# H616 register map
Vendor: Allwinner; Series: H616; File version: 0.1
CPU: other 0, little endian, MPU, no FPU, 0 interrupt priority bits
Registers are 32-bit, read-write, reset 0x0 unless marked. A register's access mark holds for its fields unless they carry their own. Offsets are from the block's base; [hi:lo] are bit positions; lines under a group give offsets from that group; {n}, {i} and the like mark numbered series; 'fields as' and 'values as' point back to an identical list; <NAME> marks a mode.

## AHUB
Base 0x05097000
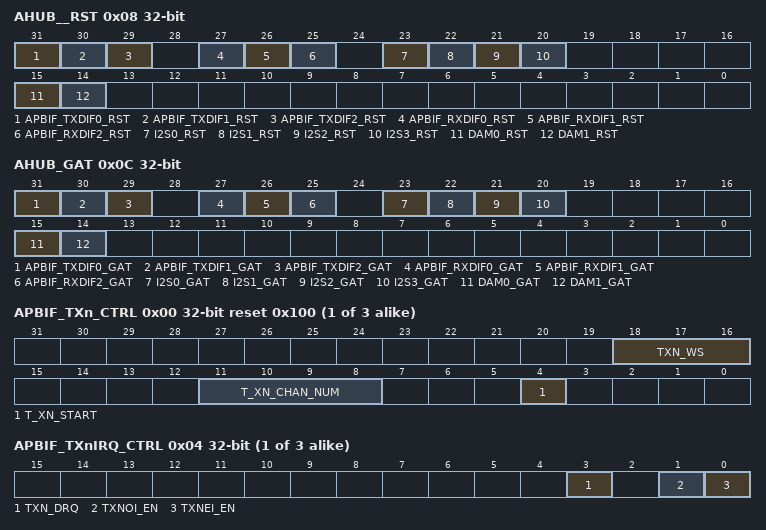
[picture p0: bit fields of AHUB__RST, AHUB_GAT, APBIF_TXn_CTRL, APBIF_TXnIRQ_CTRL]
0x08 AHUB__RST
  [all] fields
    0=Assert; 1=deassert
  [31] APBIF_TXDIF0_RST — 0: Assert 1: De-assert
  [30] APBIF_TXDIF1_RST — 0: Assert 1: De-assert
  [29] APBIF_TXDIF2_RST — 0: Assert 1: De-assert
  [27] APBIF_RXDIF0_RST — 0: Assert 1: De-assert
  [26] APBIF_RXDIF1_RST — 0: Assert 1: De-assert
  [25] APBIF_RXDIF2_RST — 0: Assert 1: De-assert
  [23-n] I2S{n}_RST (n=0..3) — 0: Assert 1: De-assert
  [15] DAM0_RST — 0: Assert 1: De-assert
  [14] DAM1_RST — 0: Assert 1: De-assert
0x0C AHUB_GAT — AHUB Gating
  [all] fields
    0=OFF (Clock is OFF); 1=ON (Clock is ON)
  [31] APBIF_TXDIF0_GAT — 0: Clock is OFF 1: Clock is ON
  [30] APBIF_TXDIF1_GAT — 0: Clock is OFF 1: Clock is ON
  [29] APBIF_TXDIF2_GAT — 0: Clock is OFF 1: Clock is ON
  [27] APBIF_RXDIF0_GAT — 0: Clock is OFF 1: Clock is ON
  [26] APBIF_RXDIF1_GAT — 0: Clock is OFF 1: Clock is ON
  [25] APBIF_RXDIF2_GAT — 0: Clock is OFF 1: Clock is ON
  [23-n] I2S{n}_GAT (n=0..3) — 0: Clock is OFF 1: Clock is ON
  [15] DAM0_GAT — 0: Clock is OFF 1: Clock is ON
  [14] DAM1_GAT — 0: Clock is OFF 1: Clock is ON
{0x10+0x30*i} _n[{i}] (i=0..2) group
  0x00 APBIF_TXn_CTRL reset 0x100 — APBIF TXn Control
    [18:16] TXN_WS — TXn_WS TX Width Select 000:Reserved 001:8-bit 010:12-bit 011:16-bit 100:20-bit 101:24-bit 110:28-bit 111:32-bit
    [11:8] T_XN_CHAN_NUM — TXn_CHAN_NUM TX Channel Number which between CPU/DMA and FIFO 0000: 1 Channel 0001: 2 Channel ... 1110: 15 Channel 1111: 16 Channel
      0=1 Channel; 1=2 Channel ; 14=15 Channel; 15=16 Channel
    [4] T_XN_START — TXn_START APBIF TX Streaming Start
  0x04 APBIF_TXnIRQ_CTRL — APBIF TXn DMA & Interrupt Control
    [all] fields
      0=Disable; 1=Enable
    [3] TXN_DRQ — TXn_DRQ TX FIFO Empty DRQ Enable 0: Disable 1: Enable
    [1] TXNOI_EN — TXnOI_EN TX FIFO Overrun Interrupt Enable 0: Disable 1: Enable
    [0] TXNEI_EN — TXnEI_EN TX FIFO Empty Interrupt Enable 0: Disable 1: Enable
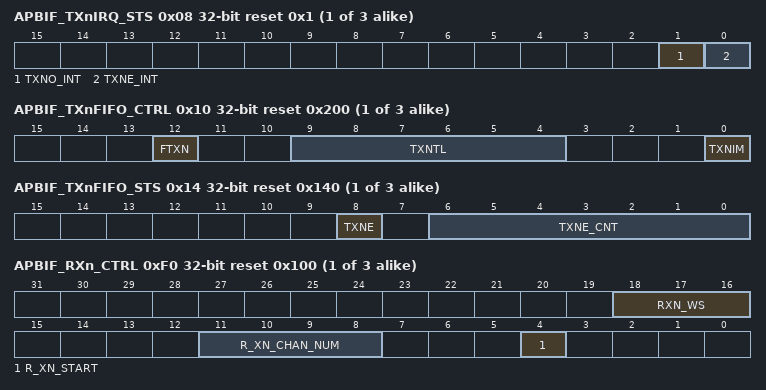
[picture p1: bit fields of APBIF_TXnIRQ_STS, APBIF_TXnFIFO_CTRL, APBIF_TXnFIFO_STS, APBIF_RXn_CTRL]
  0x08 APBIF_TXnIRQ_STS reset 0x1 — AHUB APBIF TXn DMA & Interrupt Status
    [1] TXNO_INT write-1-clears — TXnO_INT TXFIFO Overrun Pending Interrupt 0: No Pending Interrupt 1: TXFIFO Overrun Pending Interrupt Write `1` to clear this interrupt.
      0=No Pending Interrupt; 1=TXFIFO (TXFIFO Overrun Pending Interrupt Write `1` to clear this interrupt.)
    [0] TXNE_INT write-1-clears — TXnE_INT TXFIFO Empty pending Interrupt 0: No pending IRQ 1: TXFIFO Empty Pending Interrupt When Data in TXFIFO are Less than TX Trigger Level Write `1` to clear this Interrupt or automatic clear if Interrupt condition fails.
      0=No pending IRQ; 1=TXFIFO (TXFIFO Empty Pending Interrupt When Data in TXFIFO are Less than TX Trigger Level Write `1` to clear this Interrupt or automatic clear if Interrupt condition fails.)
  0x10 APBIF_TXnFIFO_CTRL reset 0x200 — AHUB APBIF TXn FIFO Control
    [12] FTXN — FTXn Write `1` to flush TX FIFO, self clear to `0`.
    [9:4] TXNTL — TXnTL TX FIFO Empty Trigger Level Interrupt and DMA request trigger level for TXFIFO normal condition Trigger Level = TXnTL
    [0] TXNIM — TXnIM TX FIFO Input Mode(Mode 0, 1) 0: Valid data at the MSB of TXFIFO register 1: Valid data at the LSB of TXFIFO register Example for 20-bit transmitted audio sample: Mode0: FIFO_I[31:0]={APB_WDATA[31:12], 12`h0} Mode1: FIFO_I[31:0]={APB_WDATA[19:0], 12`h0}
      0=Valid data at the MSB of TXFIFO register; 1=Valid data at the LSB of TXFIFO register Example for 20-bit transmitted audio sample: Mode0: FIFO_I[31:0]={APB_WDATA[31:12], 12`h0} Mode1: FIFO_I[31:0]={APB_WDATA[19:0], 12`h0}
  0x14 APBIF_TXnFIFO_STS reset 0x140 — APBIF TXn FIFO Status
    [8] TXNE ro — TXnE TXFIFO Empty 0: No Room for New Sample in TXFIFO 1: More than One Room for New Sample in TXFIFO (>= 1 Word)
      0=No Room for New Sample in TXFIFO; 1=More than One Room for New Sample in TXFIFO (>= 1 Word)
    [6:0] TXNE_CNT ro — TXnE_CNT TXFIFO Empty Space Word Counter
  0x20 APBIF_TXnFIFO
    [31:0] TXN_DATA wo — TXn_DATA TX Sample Transmitting left, right channel sample data should be written this register one by one. The left channel sample data is first and then the right channel sample.
  0x24 APBIF_TXnFIFO_CNT — APBIF TXn FIFO Counter
    [31:0] TXN_CNT — TXn_CNT TX Sample Counter The audio sample number of sending into TXFIFO. When one sample is put into TXFIFO by DMA or by host IO, the TX sample counter register increases by one. The TX sample counter register can be set to any initial value at any time. After been updated by the initial value, the counter register should counter on base of this initial value.
  0xF0 APBIF_RXn_CTRL reset 0x100 — APBIF RXn Control
    [18:16] RXN_WS — RXn_WS RX Width Select 000:Reserved 001:8-bit 010:12-bit 011:16-bit 100:20-bit 101:24-bit 110:28-bit 111:32-bit
    [11:8] R_XN_CHAN_NUM — RXn_CHAN_NUM TX Channel Number which between CPU/DMA and FIFO 0: 1 Channel 1: 2 Channel ... 14: 15 Channel 15: 16 Channel
      14=15 Channel; 15=16 Channel
    [4] R_XN_START — RXn_START APBIF RX Streaming Start
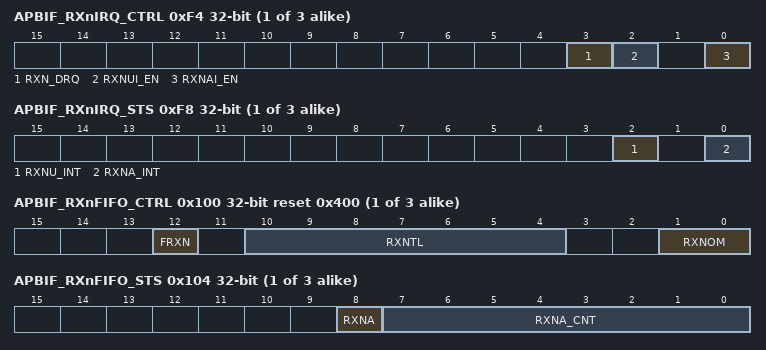
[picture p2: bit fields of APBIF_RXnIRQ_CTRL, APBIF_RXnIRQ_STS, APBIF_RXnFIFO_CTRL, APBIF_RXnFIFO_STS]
  0xF4 APBIF_RXnIRQ_CTRL — APBIF RXn DMA & Interrupt Control
    [3] RXN_DRQ — RXn_DRQ RX FIFO Data Available DRQ Enable 0: Disable 1: Enable When set to `1`, RXFIFO DMA Request line is asserted if Data is available in RXFIFO.
      0=Disable; 1=Enable When set to `1`, RXFIFO DMA Request line is asserted if Data is available in RXFIFO
    [2] RXNUI_EN — RXnUI_EN RX FIFO Underrun Interrupt Enable 0: Disable 1: Enable
      0=Disable; 1=Enable
    [0] RXNAI_EN — RXnAI_EN RX FIFO Data Available Interrupt Enable 0: Disable 1: Enable
      0=Disable; 1=Enable
  0xF8 APBIF_RXnIRQ_STS — APBIF RXn DMA & Interrupt Status
    [2] RXNU_INT write-1-clears — RXnU_INT RX FIFO Underrun Pending Interrupt 0: No Pending Interrupt 1: RXFIFO Underrun Pending Interrupt Write `1` to clear this interrupt.
      0=No Pending Interrupt; 1=RXFIFO (RXFIFO Underrun Pending Interrupt Write `1` to clear this interrupt.)
    [0] RXNA_INT write-1-clears — RXnA_INT RX FIFO Data Available Pending Interrupt 0: No Pending IRQ 1: TX FIFO Data Available Pending Interrupt When Data in RX FIFO are more than RX Trigger Level Write `1` to clear this Interrupt or Automatic clear if Interrupt condition fails
      0=No Pending IRQ; 1=TX (TX FIFO Data Available Pending Interrupt When Data in RX FIFO are more than RX Trigger Level Write `1` to clear this Interrupt or Automatic clear if Interrupt condition fails)
  0x100 APBIF_RXnFIFO_CTRL reset 0x400 — APBIF RXn FIFO Control
    [12] FRXN write-1-clears — FRXn Write `1` to flush RX FIFO, self clear to `0`.
    [10:4] RXNTL — RXnTL RX FIFO Empty Trigger Level Interrupt and DMA request trigger level for RXFIFO normal condition Trigger Level = RXnTL
    [1:0] RXNOM — RXnOM RX FIFO Output Mode(Mode 0, 1,2,3) 00: Expanding `0` at LSB of RX FIFO register 01: Expanding received sample sign bit at MSB of RX FIFO register. 10: Truncating received samples at high half-word of RX FIFO register and low half-word of RX FIFO register is filled by `0`. 11: Truncating received samples at low half-word of RX FIFO register and high half-word of RX FIFO register is expanded by its sign bit. Example for 20-bit received audio sample: Mode 0: APB_RDATA[31:0] = {FIFO_O[31:12], 12`h0}. Mode 1: APB_RDATA[31:0] = {12{FIFO_O[31]}, FIFO_O[31:12]}. Mode 2: APB_RDATA[31:0] = {FIFO_O[31:16], 16`h0}. Mode 3: APB_RDATA[31:0] = {16{FIFO_O[31]}, FIFO_O[31:16]}.
      0=Expanding `0` at LSB of RX FIFO register; 1=Expanding received sample sign bit at MSB of RX FIFO register; 2=Truncating received samples at high half-word of RX FIFO register and low half-word of RX FIFO register is filled by `0`; 3=Truncating received samples at low half-word of RX FIFO register and high half-word of RX FIFO register is expanded by its sign bit. Example for 20-bit received audio sample: Mode 0: APB_RDATA[31:0] = {FIFO_O[31:12], 12`h0}. Mode 1: APB_RDATA[31:0] = {12{FIFO_O[31]}, FIFO_O[31:12]}. Mode 2: APB_RDATA[31:0] = {FIFO_O[31:16], 16`h0}. Mode 3: APB_RDATA[31:0] = {16{FIFO_O[31]}, FIFO_O[31:16]}.
  0x104 APBIF_RXnFIFO_STS — APBIF RX0 FIFO Status
    [8] RXNA ro — RXnA RX FIFO Available 0: No available data in RX FIFO 1: More than One Sample in RX FIFO (>= 1 Word)
      0=No available data in RX FIFO; 1=More than One Sample in RX FIFO (>= 1 Word)
    [7:0] RXNA_CNT ro — RXnA_CNT RX FIFO Available Sample Word Counter
  0x108 APBIF_RXn_CONT — APBIF RXn Contact Select
    [31:12] R_XN_CONTACT_RXDIF — RXn_CONTACT_RXDIF Bit[31]:APBIF_TXDIF0 Bit[30]:APBIF_TXDIF1 Bit[29]:APBIF_TXDIF2 Bit[28]:Reserved Bit[27]:I2S0_TXDIF Bit[26]:I2S1_TXDIF(HDMI) Bit[25]:I2S2_TXDIF Bit[24]:Reserved Bit[23]:I2S3_TXDIF Bit[22~20]:Reserved Bit[19]:DAM0_TXDIF Bit[18~16]:Reserved Bit[15]:DAM1_TXDIF Bit[14~0]:Reserved When the TXDIF Contact to this RXDIF, the corresponding bit will be set.
  0x110 APBIF_RXnFIFO
    [31:0] RXN_DATA ro — RXn_DATA RX Sample Host can get one sample by reading this register. The left channel sample data is first and then the right channel sample.
  0x114 APBIF_RXnFIFO_CNT — APBIF RXn FIFO Counter
    [31:0] RXN_CNT — RXn_CNT RX Sample Counter The audio sample number of writing into RXFIFO. When one sample is write into RXFIFO by function module, the RX sample counter register increases by one. The RX sample counter register can be set to any initial value at any time. After been updated by the initial value, the counter register should counter on base of this initial value.
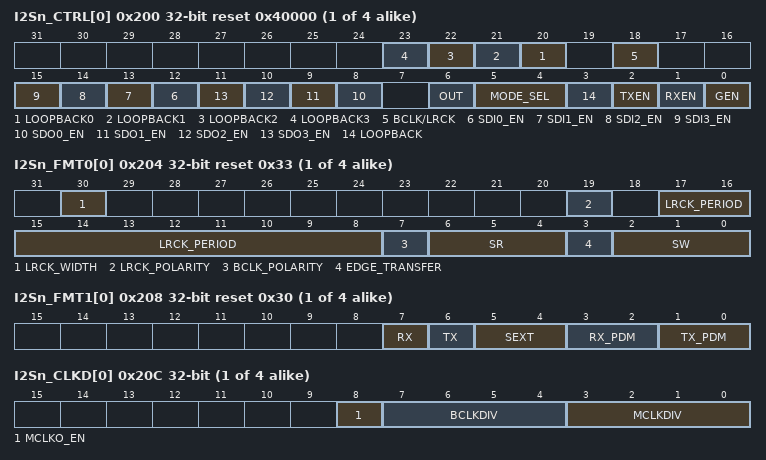
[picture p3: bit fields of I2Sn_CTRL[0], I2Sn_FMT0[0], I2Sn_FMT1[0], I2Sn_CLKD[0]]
{0x200+0x100*i} I2Sn_CTRL[{i}] (i=0..3) reset 0x40000 — I2Sn Control
  [n+20] LOOPBACK{n} (n=0..3) — Loop back test 0: Normal mode 1: Loopback test When set `1`, connecting the SDO0 with the SDI{n}
    0=Normal_mode; 1=Loopback test When set `1`, connecting the SDO0 with the SDI{n}
  [18] BCLK/LRCK — Direction 0:Input 1:Output
  [n+12] SDI{n}_EN (n=0..3) — 0:Disable, Hi-Z state 1:Enable
  [n+8] SDO{n}_EN (n=0..3) — 0:Disable, Hi-Z state 1:Enable
  [6] OUT — Mute 0: Normal transfer 1: Force DOUT to output 0
    0=Normal transfer; 1=Force DOUT to output 0
  [5:4] MODE_SEL — Mode Selection 00: PCM mode(offset 0: DSP_B; offset 1: DSP_A) 01: Left mode(offset 0: L-J Mode; offset 1: I2S mode) 10: Right-Justified mode 11: Reserved
    0=PCM (PCM mode(offset 0: DSP_B; offset 1: DSP_A)); 1=Left mode(offset 0: L-J Mode; offset 1: I2S mode); 2=right_Justified_mode
  [3] LOOPBACK — Loop back test 0: Normal mode 1: Loopback test When set `1`, connecting the SDO0 with the SDI
    0=Normal_mode; 1=Loopback test When set `1`, connecting the SDO0 with the SDI
  [2] TXEN — Transmitter Block Enable 0: Disable 1: Enable
    0=Disable; 1=Enable
  [1] RXEN — Receiver Block Enable 0: Disable 1: Enable
    0=Disable; 1=Enable
  [0] GEN — Globe Enable A disable on this bit overrides any other block or channel enables. 0: Disable 1: Enable
    0=Disable; 1=Enable
{0x204+0x100*i} I2Sn_FMT0[{i}] (i=0..3) reset 0x33 — I2Sn Format 0
  [30] LRCK_WIDTH — (Only apply in PCM mode) LRCK width 0: LRCK = 1 BCLK width (short frame) 1: LRCK = 2 BCLK width (long frame)
    0=LRCK__equals__1 (LRCK = 1 BCLK width (short frame)); 1=LRCK__equals__2 (LRCK = 2 BCLK width (long frame))
  [19] LRCK_POLARITY — When apply in I2S/Left-Justified/Right-Justified mode: 0: Left channel when LRCK is low 1: Left channel when LRCK is high When apply in PCM mode: 0: PCM LRCK asserted at the negative edge 1: PCM LRCK asserted at the positive edge
    0=low (Left channel when LRCK is low); 1=high (Left channel when LRCK is high When apply in PCM mode:); 0=PCM LRCK asserted at the negative edge; 1=PCM LRCK asserted at the positive edge
  [17:8] LRCK_PERIOD — It is used to program the number of BCLKs per channel of sample frame. This value is interpreted as follow: PCM Mode: Number of BCLKs within (Left + Right) channel width. I2S/Left-Justified/Right-Justified Mode: Number of BCLKs within each individual channel width(Left or Right) For example: N = 7 : 8 BCLKs width ... N = 1023 : 1024 BCLKs width
  [7] BCLK_POLARITY — 0: Normal mode, negative edge drive and positive edge sample 1: Invert mode, positive edge drive and negative edge sample
    0=Normal mode, negative edge drive and positive edge sample; 1=Invert mode, positive edge drive and negative edge sample
  [6:4] SR — Sample Resolution 000: Reserved 001: 8-bit 010: 12-bit 011: 16-bit 100: 20-bit 101: 24-bit 110: 28-bit 111: 32-bit
    1=_8_bit; 2=_12_bit; 3=_16_bit; 4=_20_bit; 5=_24_bit; 6=_28_bit; 7=_32_bit
  [3] EDGE_TRANSFER — 0: SDO drive data and SDI sample data at the different BCLK edge 1: SDO drive data and SDI sample data at the sample BCLK edge BCLK_PLARITY = 0, use negative edge BCLK_PLARITY = 1, use positive edge
    0=SDO drive data and SDI sample data at the different BCLK edge; 1=SDO drive data and SDI sample data at the sample BCLK edge BCLK_PLARITY = 0, use negative edge BCLK_PLARITY = 1, use positive edge
  [2:0] SW — Slot Width Select 000: Reserved 001: 8-bit 010: 12-bit 011: 16-bit 100: 20-bit 101: 24-bit 110: 28-bit 111: 32-bit
    values as SR
{0x208+0x100*i} I2Sn_FMT1[{i}] (i=0..3) reset 0x30 — I2Sn Format 1
  [7] RX — MLS MSB/LSB First Select 0: MSB First 1: LSB First
    0=MSB (MSB First); 1=LSB (LSB First)
  [6] TX — MLS MSB/LSB First Select 0: MSB First 1: LSB First
    0=MSB (MSB First); 1=LSB (LSB First)
  [5:4] SEXT — Sign Extend in slot [sample resolution < width] 00: Zeros or audio gain padding at LSB position 01: Sign extension at MSB position 10: Reserved 11: Transfer 0 after each sample in each slot
    0=Zeros or audio gain padding at LSB position; 1=Sign extension at MSB position; 3=Transfer 0 after each sample in each slot
  [3:2] RX_PDM — PCM Data Mode 00: Linear PCM 01: reserved 10: 8-bit u-law 11: 8-bit A-law
    0=Linear_PCM; 2=_8_bit_ulaw; 3=_8_bit_Alaw
  [1:0] TX_PDM — PCM Data Mode 00: Linear PCM 01: reserved 10: 8-bit u-law 11: 8-bit A-law
    0=Linear_PCM; 2=_8_bit_ulaw; 3=_8_bit_Alaw
{0x20C+0x100*i} I2Sn_CLKD[{i}] (i=0..3) — I2Sn Clock Divide
  [8] MCLKO_EN — 0: Disable MCLK Output 1: Enable MCLK Output
    0=Disable MCLK Output; 1=Enable MCLK Output
  [7:4] BCLKDIV — BCLK Divide Ratio from PLL_Audio 0000: reserved 0001: Divide by 1 0010: Divide by 2 0011: Divide by 4 0100: Divide by 6 0101: Divide by 8 0110: Divide by 12 0111: Divide by 16 1000: Divide by 24 1001: Divide by 32 1010: Divide by 48 1011: Divide by 64 1100: Divide by 96 1101: Divide by 128 1110: Divide by 176 1111: Divide by 192
    1=Divide_by_1; 2=Divide_by_2; 3=Divide_by_4; 4=Divide_by_6; 5=Divide_by_8; 6=Divide_by_12; 7=Divide_by_16; 8=Divide_by_24; 9=Divide_by_32; 10=Divide_by_48; 11=Divide_by_64; 12=Divide_by_96; 13=Divide_by_128; 14=Divide_by_176; 15=Divide_by_192
  [3:0] MCLKDIV — MCLK Divide Ratio from PLL_Audio 0000: reserved 0001: Divide by 1 0010: Divide by 2 0011: Divide by 4 0100: Divide by 6 0101: Divide by 8 0110: Divide by 12 0111: Divide by 16 1000: Divide by 24 1001: Divide by 32 1010: Divide by 48 1011: Divide by 64 1100: Divide by 96 1101: Divide by 128 1110: Divide by 176 1111: Divide by 192
    values as BCLKDIV
{0x220+0x100*i} I2Sn_RXDIF_CONT[{i}] (i=0..3) — I2Sn RXDIF Contact Select
  [31:12] R_XN_CONTACT_RXDIF — RXn_CONTACT_RXDIF Bit[31]:APBIF_TXDIF0 Bit[30]:APBIF_TXDIF1 Bit[29]:APBIF_TXDIF2 Bit[28]:Reserved Bit[27]:I2S0_TXDIF Bit[26]:I2S1_TXDIF(HDMI) Bit[25]:I2S2_TXDIF Bit[24]:Reserved Bit[23]:I2S3_TXDIF Bit[22]:Reserved Bit[21]:Reserved Bit[20]:Reserved Bit[19]:DAM0_TXDIF Bit[18]:Reserved Bit[17]:Reserved Bit[16]:Reserved Bit[15]:DAM1_TXDIF Bit[14]:Reserved Bit[13]:Reserved Bit[12]:Reserved When the TXDIF Contact to this RXDIF, the corresponding bit will be set.
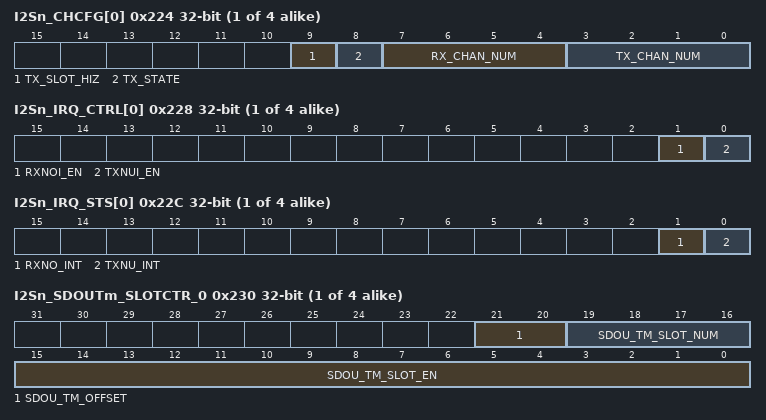
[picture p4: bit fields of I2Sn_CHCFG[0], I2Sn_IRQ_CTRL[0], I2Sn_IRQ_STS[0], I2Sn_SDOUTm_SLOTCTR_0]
{0x224+0x100*i} I2Sn_CHCFG[{i}] (i=0..3) — I2Sn Channel Configuration
  [9] TX_SLOT_HIZ — 0:Normal Mode for the Last Half Cycle of BCLK in the Slot 1:Turn to Hi-Z State for the Last Half Cycle of BCLK in the Slot
  [8] TX_STATE — 0: Transfer Level 0 When Not Transferring Slot 1:Turn to Hi-Z State(TDM) When Not Transferring Slot
    0=Transfer Level 0 When Not Transferring Slot 1:Turn to Hi-Z State(TDM) When Not Transferring Slot
  [7:4] RX_CHAN_NUM — RX Channel/Slot Number which between AHUB and I2Sn 0000: 1 channel or slot ... 0111: 8 channels or slots 1000: 9 channels or slots ... 1111: 16 channels or slots
    0=1 channel or slot ; 7=8 channels or slots; 8=9 channels or slots ; 15=16 channels or slots
  [3:0] TX_CHAN_NUM — TX Channel/Slot Number which between AHUB and I2Sn 0000: 1 channel or slot ... 0111: 8 channels or slots 1000: 9 channels or slots ... 1111: 16 channels or slots
    values as RX_CHAN_NUM
{0x228+0x100*i} I2Sn_IRQ_CTRL[{i}] (i=0..3) — I2Sn DMA & Interrupt Control
  [1] RXNOI_EN — RXnOI_EN RX FIFO Overrun Interrupt Enable 0: Disable 1: Enable
    0=Disable; 1=Enable
  [0] TXNUI_EN — TXnUI_EN TX FIFO Underrun Interrupt Enable 0: Disable 1: Enable
    0=Disable; 1=Enable
{0x22C+0x100*i} I2Sn_IRQ_STS[{i}] (i=0..3) — I2Sn DMA & Interrupt Status
  [1] RXNO_INT write-1-clears — RXnO_INT RX FIFO Overrun Pending Interrupt 0: No Pending Interrupt 1: RXFIFO Overrun Pending Interrupt Write `1` to clear this interrupt
    0=No Pending Interrupt; 1=RXFIFO (RXFIFO Overrun Pending Interrupt Write `1` to clear this interrupt)
  [0] TXNU_INT write-1-clears — TXnU_INT TX FIFO Underrun Pending Interrupt 0: No Pending Interrupt 1: TXFIFO Underrun Pending Interrupt Write `1` to clear this interrupt
    0=No Pending Interrupt; 1=TXFIFO (TXFIFO Underrun Pending Interrupt Write `1` to clear this interrupt)
{0x230+0x10*i} I2Sn_SDOUTm_SLOTCTR_{i} (i=0..3) — I2Sn Output Slot Control
  [21:20] SDOU_TM_OFFSET — SDOUTm_OFFSET SDOUT offset tune, SDOUT data offset to LRCK 0: no offset n: data is offset by n BCLKs to LRCK
  [19:16] SDOU_TM_SLOT_NUM — SDOUTm_SLOT_NUM SDOUT slot number select for each output 0000: 1 Slots ... 0111: 8 Slots 1000: 9 Slots ... 1111: 16 Slots
    0=1 Slots ; 7=8 Slots; 8=9 Slots ; 15=16 Slots
  [15:0] SDOU_TM_SLOT_EN — SDOUTm_SLOT_EN SDOUT slot enable, bit[15:0] refer to slot[15:0]. When one or more slot(s) is(are) disable, the affected slot(s) is(are) set to disable state 0: Disable 1: Enable
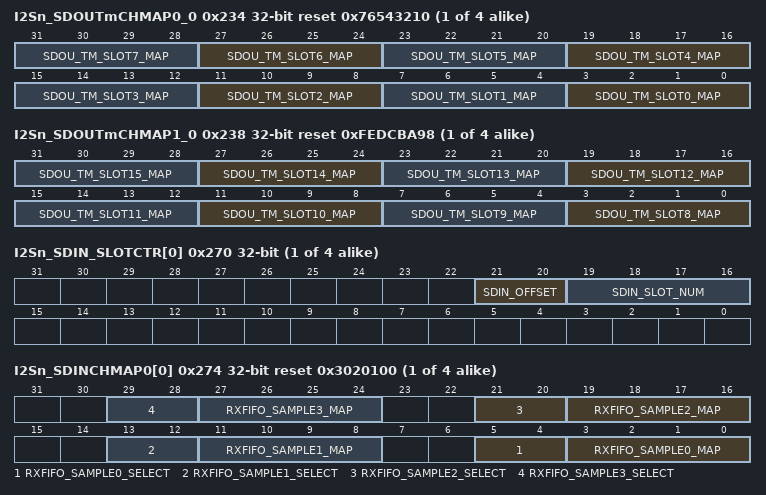
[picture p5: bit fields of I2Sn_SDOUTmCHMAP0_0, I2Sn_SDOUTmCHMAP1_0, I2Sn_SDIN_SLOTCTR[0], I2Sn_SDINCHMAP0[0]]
{0x234+0x10*i} I2Sn_SDOUTmCHMAP0_{i} reset 0x76543210 (i=0..3) — I2Sn SDOUTm Channel Mapping 0
  [all] fields
    0=1 channel data ; 15=16 channel data
  [4n+3:4n] SDOU_TM_SLOT{n}_MAP (n=0..7) — SDOUTm_SLOT{n}_MAP SDOUT Slot{n} Mapping 0000: 1 channel data ... 1111: 16 channel data
{0x238+0x10*i} I2Sn_SDOUTmCHMAP1_{i} reset 0xFEDCBA98 (i=0..3) — I2Sn SDOUTm Channel Mapping 1
  [all] fields
    0=1 channel data ; 15=16 channel data
  [4n-29:4n-32] SDOU_TM_SLOT{n}_MAP (n=8..15) — SDOUTm_SLOT{n}_MAP SDOUT Slot{n} Mapping 0000: 1 channel data ... 1111: 16 channel data
{0x270+0x100*i} I2Sn_SDIN_SLOTCTR[{i}] (i=0..3) — I2Sn Input Slot Control
  [21:20] SDIN_OFFSET — SDIN offset tune, SDIN data offset to LRCK 0: no offset n: data is offset by n BCLKs to LRCK
  [19:16] SDIN_SLOT_NUM — SDIN Slot number Select for each output 0000: 1 Slots ... 0111: 8 Slots 1000: 9 Slots ... 1111: 16 Slots
    0=1 Slots ; 7=8 Slots; 8=9 Slots ; 15=16 Slots
{0x274+0x100*i} I2Sn_SDINCHMAP0[{i}] (i=0..3) reset 0x3020100 — I2Sn SDIN Channel Mapping 0
  [8n+5:8n+4] RXFIFO_SAMPLE{n}_SELECT (n=0..3) — 00: SDI0 01: SDI1 10: SDI2 11: SDI3
    {v}=SDI{v} (v=0..3)
  [8n+3:8n] RXFIFO_SAMPLE{n}_MAP (n=0..3) — RXFIFO Sample{n} Mapping 0: 1 channel data ... 15: 16 channel data
    15=16 channel data
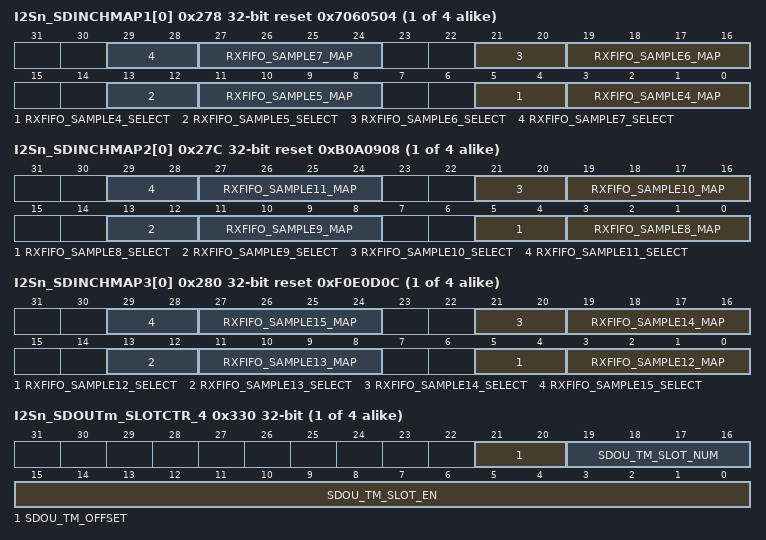
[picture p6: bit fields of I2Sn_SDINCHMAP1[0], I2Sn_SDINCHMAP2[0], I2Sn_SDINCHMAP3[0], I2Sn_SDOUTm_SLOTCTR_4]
{0x278+0x100*i} I2Sn_SDINCHMAP1[{i}] (i=0..3) reset 0x7060504 — I2Sn SDIN Channel Mapping 1
  [8n-27:8n-28] RXFIFO_SAMPLE{n}_SELECT (n=4..7) — 00: SDI0 01: SDI1 10: SDI2 11: SDI3
    {v}=SDI{v} (v=0..3)
  [8n-29:8n-32] RXFIFO_SAMPLE{n}_MAP (n=4..7) — RXFIFO Sample{n} Mapping 0: 1 channel data ... 15: 16 channel data
    15=16 channel data
{0x27C+0x100*i} I2Sn_SDINCHMAP2[{i}] (i=0..3) reset 0xB0A0908 — I2Sn SDIN Channel Mapping 2
  [8n-59:8n-60] RXFIFO_SAMPLE{n}_SELECT (n=8..11) — 00: SDI0 01: SDI1 10: SDI2 11: SDI3
    {v}=SDI{v} (v=0..3)
  [8n-61:8n-64] RXFIFO_SAMPLE{n}_MAP (n=8..11) — RXFIFO Sample{n} Mapping 0: 1 channel data ... 15: 16 channel data
    15=16 channel data
{0x280+0x100*i} I2Sn_SDINCHMAP3[{i}] (i=0..3) reset 0xF0E0D0C — I2Sn SDIN Channel Mapping 3
  [8n-91:8n-92] RXFIFO_SAMPLE{n}_SELECT (n=12..15) — 00: SDI0 01: SDI1 10: SDI2 11: SDI3
    {v}=SDI{v} (v=0..3)
  [8n-93:8n-96] RXFIFO_SAMPLE{n}_MAP (n=12..15) — RXFIFO Sample{n} Mapping 0: 1 channel data ... 15: 16 channel data
    15=16 channel data
{0x2F0+0x10*i} I2Sn_SDOUTm_SLOTCTR_{i} (i=4..7) — I2Sn Output Slot Control
  fields as I2Sn_SDOUTm_SLOTCTR_0
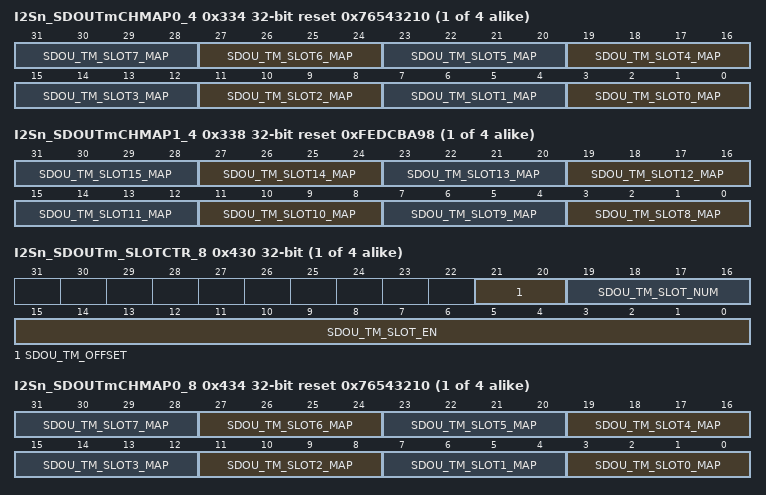
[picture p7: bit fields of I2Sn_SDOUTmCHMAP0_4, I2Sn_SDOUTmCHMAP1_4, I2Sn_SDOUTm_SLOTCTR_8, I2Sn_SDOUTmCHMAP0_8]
{0x2F4+0x10*i} I2Sn_SDOUTmCHMAP0_{i} reset 0x76543210 (i=4..7) — I2Sn SDOUTm Channel Mapping 0
  fields as I2Sn_SDOUTmCHMAP0_0
{0x2F8+0x10*i} I2Sn_SDOUTmCHMAP1_{i} reset 0xFEDCBA98 (i=4..7) — I2Sn SDOUTm Channel Mapping 1
  fields as I2Sn_SDOUTmCHMAP1_0
{0x3B0+0x10*i} I2Sn_SDOUTm_SLOTCTR_{i} (i=8..11) — I2Sn Output Slot Control
  fields as I2Sn_SDOUTm_SLOTCTR_0
{0x3B4+0x10*i} I2Sn_SDOUTmCHMAP0_{i} reset 0x76543210 (i=8..11) — I2Sn SDOUTm Channel Mapping 0
  fields as I2Sn_SDOUTmCHMAP0_0
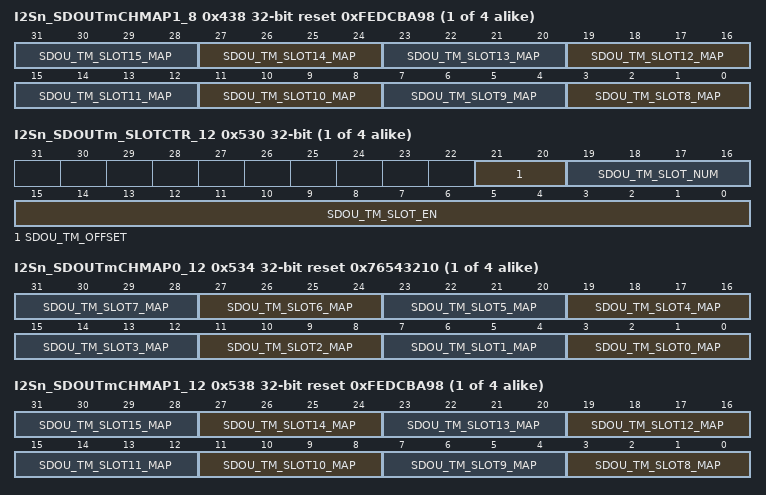
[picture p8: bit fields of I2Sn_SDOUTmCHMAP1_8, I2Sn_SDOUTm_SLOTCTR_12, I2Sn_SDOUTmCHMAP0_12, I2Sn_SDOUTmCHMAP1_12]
{0x3B8+0x10*i} I2Sn_SDOUTmCHMAP1_{i} reset 0xFEDCBA98 (i=8..11) — I2Sn SDOUTm Channel Mapping 1
  fields as I2Sn_SDOUTmCHMAP1_0
{0x470+0x10*i} I2Sn_SDOUTm_SLOTCTR_{i} (i=12..15) — I2Sn Output Slot Control
  fields as I2Sn_SDOUTm_SLOTCTR_0
{0x474+0x10*i} I2Sn_SDOUTmCHMAP0_{i} reset 0x76543210 (i=12..15) — I2Sn SDOUTm Channel Mapping 0
  fields as I2Sn_SDOUTmCHMAP0_0
{0x478+0x10*i} I2Sn_SDOUTmCHMAP1_{i} reset 0xFEDCBA98 (i=12..15) — I2Sn SDOUTm Channel Mapping 1
  fields as I2Sn_SDOUTmCHMAP1_0
{0xA00+0x80*i} _n[{i}] (i=0..1) group
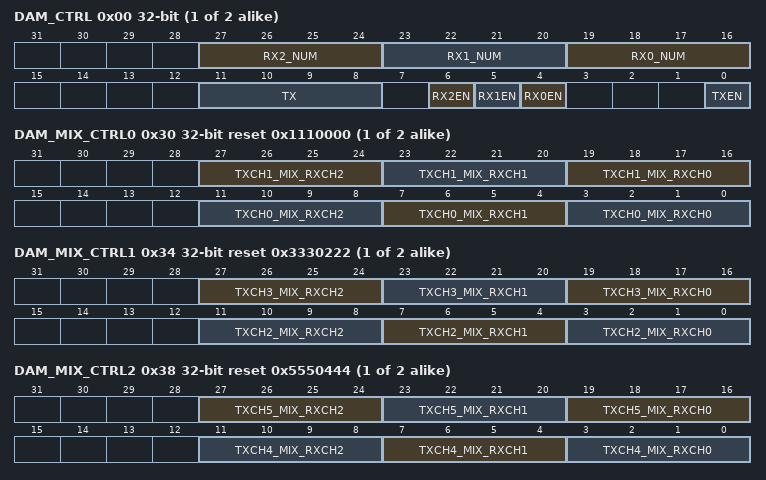
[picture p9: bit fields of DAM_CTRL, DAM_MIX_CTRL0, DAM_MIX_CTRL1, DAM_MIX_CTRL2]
  0x00 DAM_CTRL
    [27:24] RX2_NUM — RX2 Channel Num
    [23:20] RX1_NUM — RX1 Channel Num
    [19:16] RX0_NUM — RX0 Channel Num
    [11:8] TX — Channel Num
    [6] RX2EN — Receiver Enable 0: Disable 1: Enable
      0=Disable; 1=Enable
    [5] RX1EN — Receiver Enable 0: Disable 1: Enable
      0=Disable; 1=Enable
    [4] RX0EN — Receiver Enable 0: Disable 1: Enable
      0=Disable; 1=Enable
    [0] TXEN — Transmitter Enable 0: Disable 1: Enable
      0=Disable; 1=Enable
  {0x10+4j} DAM_RX{j}_SRC (j=0..2)
    [31:12] R_XN_CONTACT_RXDIF — RXn_CONTACT_RXDIF Bit[31]:APBIF_TXDIF0 Bit[30]:APBIF_TXDIF1 Bit[29]:APBIF_TXDIF2 Bit[28]:Reserved Bit[27]:I2S0_TXDIF Bit[26]:I2S1_TXDIF(HDMI) Bit[25]:I2S2_TXDIF Bit[24]:Reserved Bit[23]:I2S3_TXDIF Bit[22]:Reserved Bit[21]:Reserved Bit[20]:Reserved Bit[19]:DAM0_TXDIF0 Bit[18]:Reserved Bit[17]:Reserved Bit[16]:Reserved Bit[15]:DAM1_TXDIF0 Bit[14]:Reserved Bit[13]:Reserved Bit[12]:Reserved When the TXDIF Contact to this RXDIF, the corresponding bit will be set.
  0x30 DAM_MIX_CTRL0 reset 0x1110000
    [27:24] TXCH1_MIX_RXCH2 — RX2 Channel NUM to TXDIF Channel 1 N: TXDIF Channel 1 MIX RX2 Channel N
    [23:20] TXCH1_MIX_RXCH1 — RX1 Channel NUM to TXDIF Channel 1 N: TXDIF Channel 1 MIX RX1 Channel N
    [19:16] TXCH1_MIX_RXCH0 — RX0 Channel NUM to TXDIF Channel 1 N: TXDIF Channel 1 MIX RX0 Channel N
    [11:8] TXCH0_MIX_RXCH2 — RX2 Channel NUM to TXDIF Channel 0 N: TXDIF Channel 0 MIX RX2 Channel N
    [7:4] TXCH0_MIX_RXCH1 — RX1 Channel NUM to TXDIF Channel 0 N: TXDIF Channel 0 MIX RX1 Channel N
    [3:0] TXCH0_MIX_RXCH0 — RX0 Channel NUM to TXDIF Channel 0 N: TXDIF Channel 0 MIX RX0 Channel N
  0x34 DAM_MIX_CTRL1 reset 0x3330222
    [27:24] TXCH3_MIX_RXCH2 — RX2 Channel NUM to TXDIF Channel 3 N: TXDIF Channel 3 MIX RX2 Channel N
    [23:20] TXCH3_MIX_RXCH1 — RX1 Channel NUM to TXDIF Channel 3 N: TXDIF Channel 3 MIX RX1 Channel N
    [19:16] TXCH3_MIX_RXCH0 — RX0 Channel NUM to TXDIF Channel 3 N: TXDIF Channel 3 MIX RX0 Channel N
    [11:8] TXCH2_MIX_RXCH2 — RX2 Channel NUM to TXDIF Channel 2 N: TXDIF Channel 2 MIX RX2 Channel N
    [7:4] TXCH2_MIX_RXCH1 — RX1 Channel NUM to TXDIF Channel 2 N: TXDIF Channel 2 MIX RX1 Channel N
    [3:0] TXCH2_MIX_RXCH0 — RX0 Channel NUM to TXDIF Channel 2 N: TXDIF Channel 2 MIX RX0 Channel N
  0x38 DAM_MIX_CTRL2 reset 0x5550444
    [27:24] TXCH5_MIX_RXCH2 — RX2 Channel NUM to TXDIF Channel 5 N: TXDIF Channel 5 MIX RX2 Channel N
    [23:20] TXCH5_MIX_RXCH1 — RX1 Channel NUM to TXDIF Channel 5 N: TXDIF Channel 5 MIX RX1 Channel N
    [19:16] TXCH5_MIX_RXCH0 — RX0 Channel NUM to TXDIF Channel 5 N: TXDIF Channel 5 MIX RX0 Channel N
    [11:8] TXCH4_MIX_RXCH2 — RX2 Channel NUM to TXDIF Channel 4 N: TXDIF Channel 4 MIX RX2 Channel N
    [7:4] TXCH4_MIX_RXCH1 — RX1 Channel NUM to TXDIF Channel 4 N: TXDIF Channel 2 MIX RX1 Channel N
    [3:0] TXCH4_MIX_RXCH0 — RX0 Channel NUM to TXDIF Channel 4 N: TXDIF Channel 4 MIX RX0 Channel N
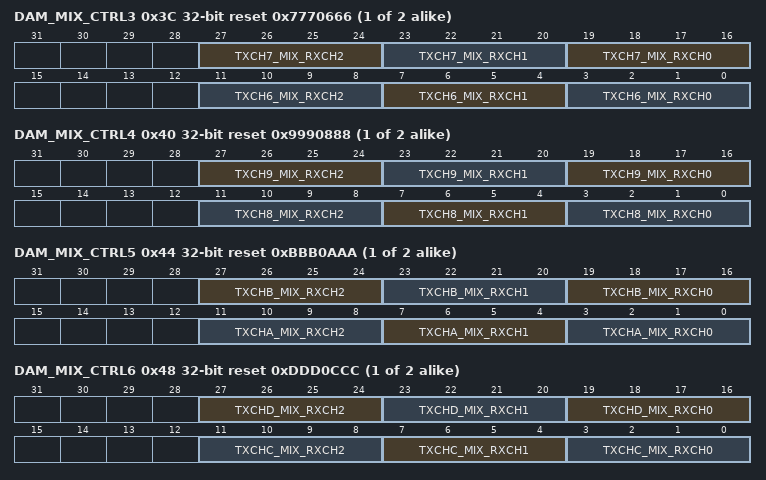
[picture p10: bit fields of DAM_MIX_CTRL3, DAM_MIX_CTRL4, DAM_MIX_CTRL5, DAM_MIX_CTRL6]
  0x3C DAM_MIX_CTRL3 reset 0x7770666
    [27:24] TXCH7_MIX_RXCH2 — RX2 Channel NUM to TXDIF Channel 7 N: TXDIF Channel 7 MIX RX2 Channel N
    [23:20] TXCH7_MIX_RXCH1 — RX1 Channel NUM to TXDIF Channel 7 N: TXDIF Channel 7 MIX RX1 Channel N
    [19:16] TXCH7_MIX_RXCH0 — RX0 Channel NUM to TXDIF Channel 7 N: TXDIF Channel 7 MIX RX0 Channel N
    [11:8] TXCH6_MIX_RXCH2 — RX2 Channel NUM to TXDIF Channel 6 N: TXDIF Channel 6 MIX RX2 Channel N
    [7:4] TXCH6_MIX_RXCH1 — RX1 Channel NUM to TXDIF Channel 6 N: TXDIF Channel 6 MIX RX1 Channel N
    [3:0] TXCH6_MIX_RXCH0 — RX0 Channel NUM to TXDIF Channel 6 N: TXDIF Channel 6 MIX RX0 Channel N
  0x40 DAM_MIX_CTRL4 reset 0x9990888
    [27:24] TXCH9_MIX_RXCH2 — RX2 Channel NUM to TXDIF Channel 9 N: TXDIF Channel 9 MIX RX2 Channel N
    [23:20] TXCH9_MIX_RXCH1 — RX1 Channel NUM to TXDIF Channel 9 N: TXDIF Channel 9 MIX RX1 Channel N
    [19:16] TXCH9_MIX_RXCH0 — RX0 Channel NUM to TXDIF Channel 9 N: TXDIF Channel 9 MIX RX0 Channel N
    [11:8] TXCH8_MIX_RXCH2 — RX2 Channel NUM to TXDIF Channel 8 N: TXDIF Channel 8 MIX RX2 Channel N
    [7:4] TXCH8_MIX_RXCH1 — RX1 Channel NUM to TXDIF Channel 8 N: TXDIF Channel 8 MIX RX1 Channel N
    [3:0] TXCH8_MIX_RXCH0 — RX0 Channel NUM to TXDIF Channel 8 N: TXDIF Channel 8 MIX RX0 Channel N
  0x44 DAM_MIX_CTRL5 reset 0xBBB0AAA
    [27:24] TXCHB_MIX_RXCH2 — RX2 Channel NUM to TXDIF Channel B N: TXDIF Channel B MIX RX2 Channel N
    [23:20] TXCHB_MIX_RXCH1 — RX1 Channel NUM to TXDIF Channel B N: TXDIF Channel B MIX RX1 Channel N
    [19:16] TXCHB_MIX_RXCH0 — RX0 Channel NUM to TXDIF Channel B N: TXDIF Channel B MIX RX0 Channel N
    [11:8] TXCHA_MIX_RXCH2 — RX2 Channel NUM to TXDIF Channel A N: TXDIF Channel A MIX RX2 Channel N
    [7:4] TXCHA_MIX_RXCH1 — RX1 Channel NUM to TXDIF Channel A N: TXDIF Channel A MIX RX1 Channel N
    [3:0] TXCHA_MIX_RXCH0 — RX0 Channel NUM to TXDIF Channel A N: TXDIF Channel A MIX RX0 Channel N
  0x48 DAM_MIX_CTRL6 reset 0xDDD0CCC
    [27:24] TXCHD_MIX_RXCH2 — RX2 Channel NUM to TXDIF Channel D N: TXDIF Channel D MIX RX2 Channel N
    [23:20] TXCHD_MIX_RXCH1 — RX1 Channel NUM to TXDIF Channel D N: TXDIF Channel D MIX RX1 Channel N
    [19:16] TXCHD_MIX_RXCH0 — RX0 Channel NUM to TXDIF Channel D N: TXDIF Channel D MIX RX0 Channel N
    [11:8] TXCHC_MIX_RXCH2 — RX2 Channel NUM to TXDIF Channel C N: TXDIF Channel C MIX RX2 Channel N
    [7:4] TXCHC_MIX_RXCH1 — RX1 Channel NUM to TXDIF Channel C N: TXDIF Channel C MIX RX1 Channel N
    [3:0] TXCHC_MIX_RXCH0 — RX0 Channel NUM to TXDIF Channel C N: TXDIF Channel C MIX RX0 Channel N
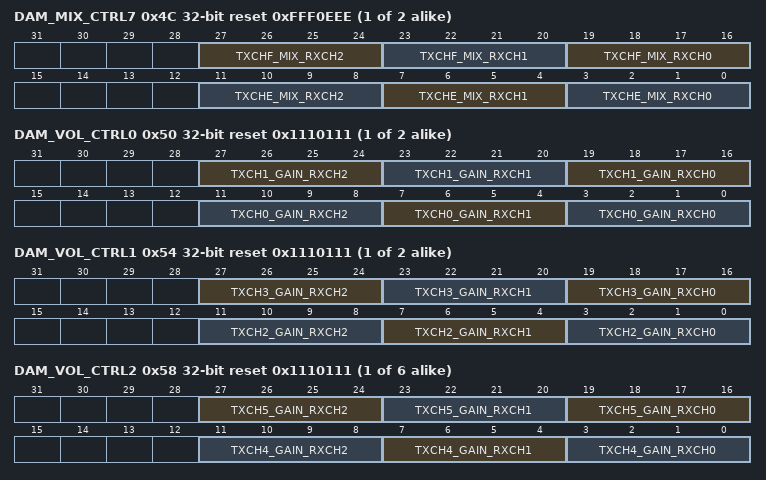
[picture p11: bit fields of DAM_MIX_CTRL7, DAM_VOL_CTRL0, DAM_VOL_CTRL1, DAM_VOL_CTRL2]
  0x4C DAM_MIX_CTRL7 reset 0xFFF0EEE
    [27:24] TXCHF_MIX_RXCH2 — RX2 Channel NUM to TXDIF Channel F N: TXDIF Channel F MIX RX2 Channel N
    [23:20] TXCHF_MIX_RXCH1 — RX1 Channel NUM to TXDIF Channel F N: TXDIF Channel F MIX RX1 Channel N
    [19:16] TXCHF_MIX_RXCH0 — RX0 Channel NUM to TXDIF Channel F N: TXDIF Channel F MIX RX0 Channel N
    [11:8] TXCHE_MIX_RXCH2 — RX2 Channel NUM to TXDIF Channel E N: TXDIF Channel E MIX RX2 Channel N
    [7:4] TXCHE_MIX_RXCH1 — RX1 Channel NUM to TXDIF Channel E N: TXDIF Channel E MIX RX1 Channel N
    [3:0] TXCHE_MIX_RXCH0 — RX0 Channel NUM to TXDIF Channel E N: TXDIF Channel E MIX RX0 Channel N
  0x50 DAM_VOL_CTRL0 reset 0x1110111
    [all] fields
      0=Mute; 1=_0dB; 2=_minus_6dB (-6dB 0100:-12dB Others: Reserved)
    [27:24] TXCH1_GAIN_RXCH2 — RX2 Channel NUM to TXDIF Channel 1 Gain 0000: Mute 0001: 0dB 0010: -6dB 0100:-12dB Others: Reserved
    [23:20] TXCH1_GAIN_RXCH1 — RX1 Channel NUM to TXDIF Channel 1 Gain 0000: Mute 0001: 0dB 0010: -6dB 0100:-12dB Others: Reserved
    [19:16] TXCH1_GAIN_RXCH0 — RX0 Channel NUM to TXDIF Channel 1 Gain 0000: Mute 0001: 0dB 0010: -6dB 0100:-12dB Others: Reserved
    [11:8] TXCH0_GAIN_RXCH2 — RX2 Channel NUM to TXDIF Channel 0 Gain 0000: Mute 0001: 0dB 0010: -6dB 0100:-12dB Others: Reserved
    [7:4] TXCH0_GAIN_RXCH1 — RX1 Channel NUM to TXDIF Channel 0 Gain 0000: Mute 0001: 0dB 0010: -6dB 0100:-12dB Others: Reserved
    [3:0] TXCH0_GAIN_RXCH0 — RX0 Channel NUM to TXDIF Channel 0 Gain 0000: Mute 0001: 0dB 0010: -6dB 0100:-12dB Others: Reserved
  0x54 DAM_VOL_CTRL1 reset 0x1110111
    [27:24] TXCH3_GAIN_RXCH2 — RX2 Channel NUM to TXDIF Channel 3 Gain 0000: Mute 0001: 0dB 0010: -6dB 0100:-12dB Others: Reserved
      values as the fields of _n[0].DAM_VOL_CTRL0
    [23:20] TXCH3_GAIN_RXCH1 — RX1 Channel NUM to TXDIF Channel 3 Gain 0000: Mute 0001: 0dB 0010: -6dB 0100:-12dB Others: Reserved
      values as the fields of _n[0].DAM_VOL_CTRL0
    [19:16] TXCH3_GAIN_RXCH0 — RX0 Channel NUM to TXDIF Channel 3 Gain 0000: Mute 0001: 0dB 0010: -6dB 0100: -12dB Others: Reserved
      0=Mute; 1=_0dB; 2=_minus_6dB (-6dB); 4=_minus_12dB (-12dB Others: Reserved)
    [11:8] TXCH2_GAIN_RXCH2 — RX2 Channel NUM to TXDIF Channel 2 Gain 0000: Mute 0001: 0dB 0010: -6dB 0100:-12dB Others: Reserved
      values as the fields of _n[0].DAM_VOL_CTRL0
    [7:4] TXCH2_GAIN_RXCH1 — RX1 Channel NUM to TXDIF Channel 2 Gain 0000: Mute 0001: 0dB 0010: -6dB 0100:-12dB Others: Reserved
      values as the fields of _n[0].DAM_VOL_CTRL0
    [3:0] TXCH2_GAIN_RXCH0 — RX0 Channel NUM to TXDIF Channel 2 Gain 0000: Mute 0001: 0dB 0010: -6dB 0100:-12dB Others: Reserved
      values as the fields of _n[0].DAM_VOL_CTRL0
  {0x50+4j} DAM_VOL_CTRL{j} reset 0x1110111 (j=2..4)
    [all] fields
      values as the fields of _n[0].DAM_VOL_CTRL0
    [27:24] TXCH{2j+1}_GAIN_RXCH2 — RX2 Channel NUM to TXDIF Channel {2j+1} Gain 0000: Mute 0001: 0dB 0010: -6dB 0100:-12dB Others: Reserved
    [23:20] TXCH{2j+1}_GAIN_RXCH1 — RX1 Channel NUM to TXDIF Channel {2j+1} Gain 0000: Mute 0001: 0dB 0010: -6dB 0100:-12dB Others: Reserved
    [19:16] TXCH{2j+1}_GAIN_RXCH0 — RX0 Channel NUM to TXDIF Channel {2j+1} Gain 0000: Mute 0001: 0dB 0010: -6dB 0100:-12dB Others: Reserved
    [11:8] TXCH{2j}_GAIN_RXCH2 — RX2 Channel NUM to TXDIF Channel {2j} Gain 0000: Mute 0001: 0dB 0010: -6dB 0100:-12dB Others: Reserved
    [7:4] TXCH{2j}_GAIN_RXCH1 — RX1 Channel NUM to TXDIF Channel {2j} Gain 0000: Mute 0001: 0dB 0010: -6dB 0100:-12dB Others: Reserved
    [3:0] TXCH{2j}_GAIN_RXCH0 — RX0 Channel NUM to TXDIF Channel {2j} Gain 0000: Mute 0001: 0dB 0010: -6dB 0100:-12dB Others: Reserved
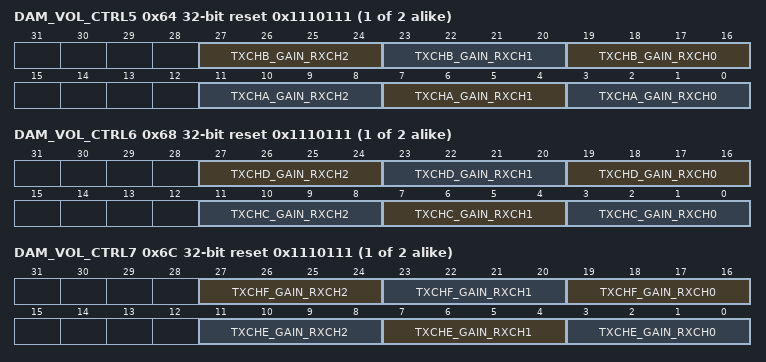
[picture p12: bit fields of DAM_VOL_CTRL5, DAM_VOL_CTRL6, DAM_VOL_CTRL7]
  0x64 DAM_VOL_CTRL5 reset 0x1110111
    [all] fields
      values as the fields of _n[0].DAM_VOL_CTRL0
    [27:24] TXCHB_GAIN_RXCH2 — RX2 Channel NUM to TXDIF Channel B Gain 0000: Mute 0001: 0dB 0010: -6dB 0100:-12dB Others: Reserved
    [23:20] TXCHB_GAIN_RXCH1 — RX1 Channel NUM to TXDIF Channel B Gain 0000: Mute 0001: 0dB 0010: -6dB 0100:-12dB Others: Reserved
    [19:16] TXCHB_GAIN_RXCH0 — RX0 Channel NUM to TXDIF Channel B Gain 0000: Mute 0001: 0dB 0010: -6dB 0100:-12dB Others: Reserved
    [11:8] TXCHA_GAIN_RXCH2 — RX2 Channel NUM to TXDIF Channel A Gain 0000: Mute 0001: 0dB 0010: -6dB 0100:-12dB Others: Reserved
    [7:4] TXCHA_GAIN_RXCH1 — RX1 Channel NUM to TXDIF Channel A Gain 0000: Mute 0001: 0dB 0010: -6dB 0100:-12dB Others: Reserved
    [3:0] TXCHA_GAIN_RXCH0 — RX0 Channel NUM to TXDIF Channel A Gain 0000: Mute 0001: 0dB 0010: -6dB 0100:-12dB Others: Reserved
  0x68 DAM_VOL_CTRL6 reset 0x1110111
    [all] fields
      values as the fields of _n[0].DAM_VOL_CTRL0
    [27:24] TXCHD_GAIN_RXCH2 — RX2 Channel NUM to TXDIF Channel D Gain 0000: Mute 0001: 0dB 0010: -6dB 0100:-12dB Others: Reserved
    [23:20] TXCHD_GAIN_RXCH1 — RX1 Channel NUM to TXDIF Channel D Gain 0000: Mute 0001: 0dB 0010: -6dB 0100:-12dB Others: Reserved
    [19:16] TXCHD_GAIN_RXCH0 — RX0 Channel NUM to TXDIF Channel D Gain 0000: Mute 0001: 0dB 0010: -6dB 0100:-12dB Others: Reserved
    [11:8] TXCHC_GAIN_RXCH2 — RX2 Channel NUM to TXDIF Channel C Gain 0000: Mute 0001: 0dB 0010: -6dB 0100:-12dB Others: Reserved
    [7:4] TXCHC_GAIN_RXCH1 — RX1 Channel NUM to TXDIF Channel C Gain 0000: Mute 0001: 0dB 0010: -6dB 0100:-12dB Others: Reserved
    [3:0] TXCHC_GAIN_RXCH0 — RX0 Channel NUM to TXDIF Channel C Gain 0000: Mute 0001: 0dB 0010: -6dB 0100:-12dB Others: Reserved
  0x6C DAM_VOL_CTRL7 reset 0x1110111
    [all] fields
      values as the fields of _n[0].DAM_VOL_CTRL0
    [27:24] TXCHF_GAIN_RXCH2 — RX2 Channel NUM to TXDIF Channel F Gain 0000: Mute 0001: 0dB 0010: -6dB 0100:-12dB Others: Reserved
    [23:20] TXCHF_GAIN_RXCH1 — RX1 Channel NUM to TXDIF Channel F Gain 0000: Mute 0001: 0dB 0010: -6dB 0100:-12dB Others: Reserved
    [19:16] TXCHF_GAIN_RXCH0 — RX0 Channel NUM to TXDIF Channel F Gain 0000: Mute 0001: 0dB 0010: -6dB 0100:-12dB Others: Reserved
    [11:8] TXCHE_GAIN_RXCH2 — RX2 Channel NUM to TXDIF Channel E Gain 0000: Mute 0001: 0dB 0010: -6dB 0100:-12dB Others: Reserved
    [7:4] TXCHE_GAIN_RXCH1 — RX1 Channel NUM to TXDIF Channel E Gain 0000: Mute 0001: 0dB 0010: -6dB 0100:-12dB Others: Reserved
    [3:0] TXCHE_GAIN_RXCH0 — RX0 Channel NUM to TXDIF Channel E Gain 0000: Mute 0001: 0dB 0010: -6dB 0100:-12dB Others: Reserved
